# DSS_DSI0_DSI_TOP_VBUSP_CFG_DSI_0_DSI register map
Vendor: Texas Instruments
Peripheral module from a debugger description file (folder J7ES).
Registers are 32-bit, read-write, reset 0x0 unless marked. A register's access mark holds for its fields unless they carry their own. Offsets are as the file gives them; lines under a group give offsets from that group; [hi:lo] are bit positions; {n}, {i} and the like mark numbered series; 'fields as' and 'values as' point back to an identical list; <NAME> marks a mode.

## DSS_DSI0_DSI_TOP_VBUSP_CFG_DSI_0_DSI
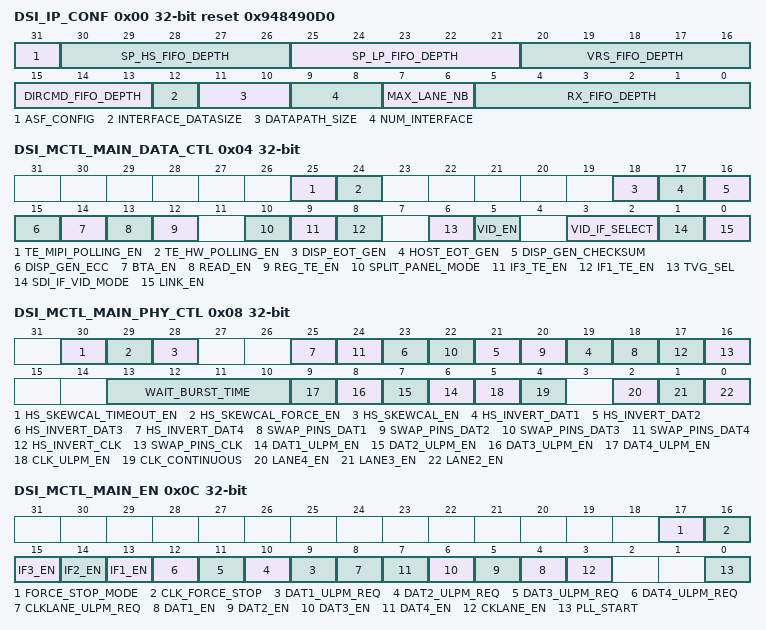
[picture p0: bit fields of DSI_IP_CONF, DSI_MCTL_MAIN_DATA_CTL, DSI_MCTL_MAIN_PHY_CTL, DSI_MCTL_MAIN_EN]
0x00 DSI_IP_CONF ro reset 0x948490D0 — IP Configuration for Controller
  [31] ASF_CONFIG — Active Safety Features [ASF] Configuration:
  [30:26] SP_HS_FIFO_DEPTH — SP_HS_FIFO_DEPTH : HS FIFO depth in sending path.
  [25:21] SP_LP_FIFO_DEPTH — SP_LP_FIFO_DEPTH : LP FIFO depth in sending path.
  [20:16] VRS_FIFO_DEPTH — VRS_FIFO_DEPTH : FIFO depth in the VRS block.
  [15:13] DIRCMD_FIFO_DEPTH — Direct Command FIFO Depth
  [12] INTERFACE_DATASIZE — SDI interface data width:
  [11:10] DATAPATH_SIZE — Internal Datapath.width
  [9:8] NUM_INTERFACE — Max Number of SDI interfaces
  [7:6] MAX_LANE_NB — Max Number of Lanes
  [5:0] RX_FIFO_DEPTH
0x04 DSI_MCTL_MAIN_DATA_CTL — Main Control - main control setting for datapath
  [25] TE_MIPI_POLLING_EN — TE_MIPI_POLLING_EN: enables TE Polling feature following MIPI recommendations [polling by software]
  [24] TE_HW_POLLING_EN — TE_HW_POLLING_EN: enables TE Polling feature following internal solution
  [18] DISP_EOT_GEN — DISP_EOT_GEN: display adds an EOT packet to its LPDT transfers
  [17] HOST_EOT_GEN — HOST_EOT_GEN: generates or not the EOT packet after a transfer in HS.
  [16] DISP_GEN_CHECKSUM — DISP_GEN_CHECKSUM: display generates checksum on its response packets.
  [15] DISP_GEN_ECC — DISP_GEN_ECC: display generates ECC on its response packets
  [14] BTA_EN — BTA_EN: enables BTA
  [13] READ_EN — READ_EN: enables read operation
  [12] REG_TE_EN — REG_TE_EN: enables Tearing Effect from register
  [10] SPLIT_PANEL_MODE — SPLIT_PANEL_MODE: when enabled, DSC stage controls data for split panel signle DPHY link
  [9] IF3_TE_EN — IF3_TE_EN: enables Tearing Effect on interface 3.
  [8] IF1_TE_EN — IF1_TE_EN: enables Tearing Effect on interface 1.
  [6] TVG_SEL — TVG_SEL: Test Video Generator is enabled [it is not the start signal!] - should not be set if if1_en = 1 and if1_mode = 1 [see
  [5] VID_EN — VID_EN: enables the video stream generator
  [3:2] VID_IF_SELECT — VID_IF_SELECT: Determines which video interface is active
  [1] SDI_IF_VID_MODE
  [0] LINK_EN — LINK_EN: enables [or not] the link]
0x08 DSI_MCTL_MAIN_PHY_CTL — Main control setting for the physical lanes and drive the static signals for D-PHY clock lane
  [30] HS_SKEWCAL_TIMEOUT_EN — HS_SKEWCAL_TIMEOUT_EN: Activate the HS SkewCal Control to occur after a timeout.
  [29] HS_SKEWCAL_FORCE_EN — HS_SKEWCAL_FORCE_EN: Force the HS SkewCal Control to occur immediately
  [28] HS_SKEWCAL_EN — HS_SKEWCAL_EN: activate the HS SkewCal Control at start of HS Transmission
  [2n+17] HS_INVERT_DAT{n} (n=1..4) — HS_INVERT_DAT
  [2n+16] SWAP_PINS_DAT{n} (n=1..4) — SWAP_PINS_DAT
  [17] HS_INVERT_CLK — HS_INVERT_CLK: invert HS signal on clock lane
  [16] SWAP_PINS_CLK — SWAP_PINS_CLK: swap pins on clock lane
  [13:10] WAIT_BURST_TIME — WAIT_BURST_TIME: delay to respect between two HS bursts.
  [n+5] DAT{n}_ULPM_EN (n=1..4) — DAT{n}_ULPM_EN: data lane {n} can be switched in ULP mode
  [5] CLK_ULPM_EN — CLK_ULPM_EN: specifies that clock lane can be switched in ULP mode [on demand]
  [4] CLK_CONTINUOUS — CLK_CONTINUOUS: clock lane should remain in HS sending mode [no return in STOP state]
  [2] LANE4_EN — LANE4_EN: enables the fourth lane [ controls DCB FSM]
  [1] LANE3_EN — LANE3_EN: enables the third lane [ controls DCB FSM]
  [0] LANE2_EN — LANE2_EN: enables the second lane [ controls DCB FSM]
0x0C DSI_MCTL_MAIN_EN — Control start/stop of the DSI link
  [17] FORCE_STOP_MODE — FORCE_STOP_MODE: when enabled, data lanes are forced back in STOP mode - this value should remain asserted for 10 us minimum
  [16] CLK_FORCE_STOP — CLK_FORCE_STOP : force clock lanes back in STOP mode - this value should remain asserted for 10 us minimum
  [15] IF3_EN — IF3_EN: enables DSC interface [i.e.
  [14] IF2_EN — IF2_EN: enables DPI interface [i.e.
  [13] IF1_EN — IF1_EN: enables SDI interface [i.e.
  [n+8] DAT{n}_ULPM_REQ (n=1..4) — DAT{n}_ULPM_REQ: switches data lane {n} in ULP mode
  [8] CLKLANE_ULPM_REQ — CLKLANE_ULPM_REQ: switches clock lane in ULP mode
  [n+3] DAT{n}_EN (n=1..4)
  [3] CKLANE_EN
  [0] PLL_START — PLL_START: enables the PLL [when set, the PLL is started]
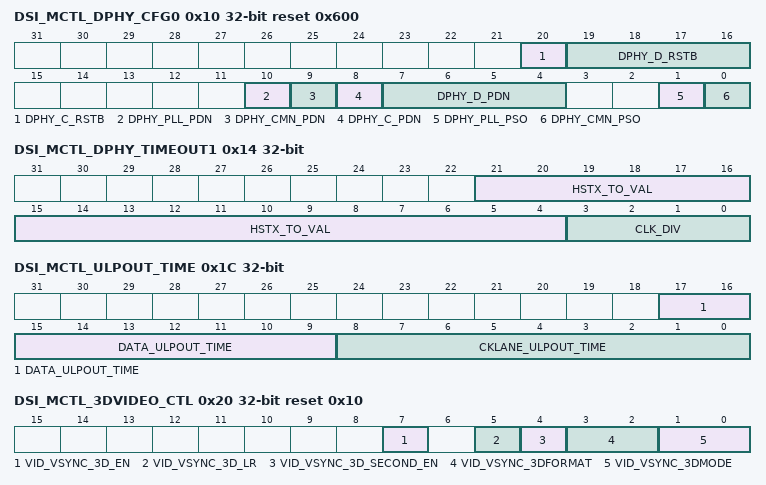
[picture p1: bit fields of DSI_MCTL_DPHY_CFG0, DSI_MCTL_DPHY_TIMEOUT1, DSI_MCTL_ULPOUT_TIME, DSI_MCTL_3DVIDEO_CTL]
0x10 DSI_MCTL_DPHY_CFG0 reset 0x600 — DPHY Power and Reset Control
  [20] DPHY_C_RSTB — Drives dphy_c_rstb output
  [19:16] DPHY_D_RSTB — Drives dphy_d_rstb output
  [10] DPHY_PLL_PDN — Drives dphy_pll_pdn output
  [9] DPHY_CMN_PDN — Drives dphy_cmn_pdn output
  [8] DPHY_C_PDN — Drives dphy_c_pdn output
  [7:4] DPHY_D_PDN — Drives dphy_d_pdn output
  [1] DPHY_PLL_PSO — Drives dphy_pll_pso output
  [0] DPHY_CMN_PSO — Drives dphy_cmn_pso output
0x14 DSI_MCTL_DPHY_TIMEOUT1 — Main DPHY time-out settings. To better understand the way this register is used, please refer to Section : DSI checks (DC) - the counters are based on tx_byte_hs_clk and NOT on sys_clk
  [21:4] HSTX_TO_VAL — HSTX_TO_VAL: HS TX time-out detection value
  [3:0] CLK_DIV — CLK_DIV: clock division ratio
0x18 DSI_MCTL_DPHY_TIMEOUT2 — To better understand the way this register is used, please refer to Section : DSI checks (DC) - the counters are on tx_byte_hs_clk and not on sys_clk
  [17:0] LPRX_TO_VAL — LPRX_TO_VAL: LP RX time-out detection value
0x1C DSI_MCTL_ULPOUT_TIME — Specify time to leave ULP mode. The time-out is reached when the ulpout counter reaches 1000x xxx_ulpout_time and is based upon the system clock
  [17:9] DATA_ULPOUT_TIME — DATA_ULPOUT_TIME: specify what the duration is to leave ULP mode is [for data lane[s] in system clock cycles
  [8:0] CKLANE_ULPOUT_TIME — CKLANE_ULPOUT_TIME: specify what the duration is to leave ULP mode is [for clock lane] in system clock cycles
0x20 DSI_MCTL_3DVIDEO_CTL reset 0x10 — 3D Video mode stream control
  [7] VID_VSYNC_3D_EN — VID_VSYNC_3D_EN: Enable 3D Control this selects the 3D operation for VSYNC and video data control
  [5] VID_VSYNC_3D_LR — VID_VSYNC_3D_LR: When 3D mode is enabled, this allows to choose which field to start the video stream
  [4] VID_VSYNC_3D_SECOND_EN — VID_VSYNC_3D_SECOND_EN: When 3D mode is enabled, this allows to choose if a second VSYNC is enabled between L and R images
  [3:2] VID_VSYNC_3DFORMAT — VID_VSYNC_3DFORMAT: video 3D Format for VSYNC Control Parameter1
  [1:0] VID_VSYNC_3DMODE — VID_VSYNC_3DMODE: video 3D mode for VSYNC Control Parameter1
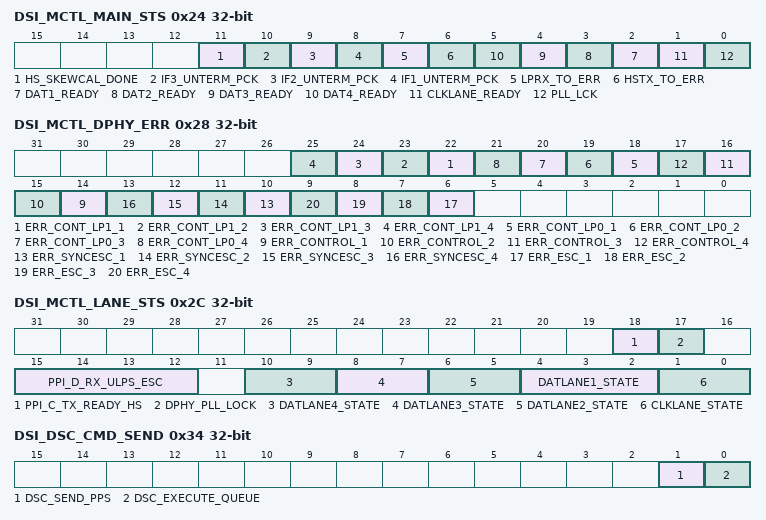
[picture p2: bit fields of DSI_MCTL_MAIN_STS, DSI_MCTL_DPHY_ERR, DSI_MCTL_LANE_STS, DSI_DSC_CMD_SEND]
0x24 DSI_MCTL_MAIN_STS ro — Status of the DSI link
  [11] HS_SKEWCAL_DONE — HS_SKEWCAL_DONE: HS SkewCal Control Done at start of HS Transmission
  [10] IF3_UNTERM_PCK — IF3_UNTERM_PCK: Indicates an unterminated packet on DSC interface
  [9] IF2_UNTERM_PCK — IF2_UNTERM_PCK: Indicates an unterminated packet on DPI interface
  [8] IF1_UNTERM_PCK — IF1_UNTERM_PCK: Indicates an unterminated packet on SDI Interface
  [7] LPRX_TO_ERR — LPRX_TO_ERR: Indicates an LP_RX time-out error
  [6] HSTX_TO_ERR — HSTX_TO_ERR: Indicates an HS_TX time-out error
  [n+1] DAT{n}_READY (n=1..4) — DAT{n}_READY: Indicates data lane {n} is ready
  [1] CLKLANE_READY — CLKLANE_READY: Indicates the clock lane is ready [normal DSI operation can start]
  [0] PLL_LCK — PLL_LCK: Indicates PLL is locked - data coming from DCB [if DSI link is PLL master] or copy of pll_en [if DSI link is slave]
0x28 DSI_MCTL_DPHY_ERR ro — Errors reported from DPHY lanes - See description in DPHY inputs and outputs
  [n+21] ERR_CONT_LP1_{n} (n=1..4), [n+17] ERR_CONT_LP0_{n} (n=1..4), [n+13] ERR_CONTROL_{n} (n=1..4), [n+9] ERR_SYNCESC_{n} (n=1..4), [n+5] ERR_ESC_{n} (n=1..4)
0x2C DSI_MCTL_LANE_STS ro — DPHY Lane and PLL status information
  [18] PPI_C_TX_READY_HS — Value of ppi_c_tx_ready_hs input
  [17] DPHY_PLL_LOCK — Value of dphy_pll_lock input
  [15:12] PPI_D_RX_ULPS_ESC — Value of ppi_d_rx_ulps_esc input
  [10:9] DATLANE4_STATE — DATLANE4_STATE: state of the data lane 4
  [8:7] DATLANE3_STATE — DATLANE3_STATE: state of the data lane 3
  [6:5] DATLANE2_STATE — DATLANE2_STATE: state of the data lane 2
  [4:2] DATLANE1_STATE — DATLANE1_STATE: state of the data lane 1
  [1:0] CLKLANE_STATE — CLKLANE_STATE: state of the clock lane
0x30 DSI_DSC_MODE_CTL — DSC Mode Control register
  [0] DSC_MODE_EN — Enable DSC Mode Controls
0x34 DSI_DSC_CMD_SEND wo — DSC Command Control register. Write one to perform PPS set transfer or Execute Queue commands
  [1] DSC_SEND_PPS — Send PPS Command and Payload to the display
  [0] DSC_EXECUTE_QUEUE — Send Execute Queue Command to Synchonise the display drivers
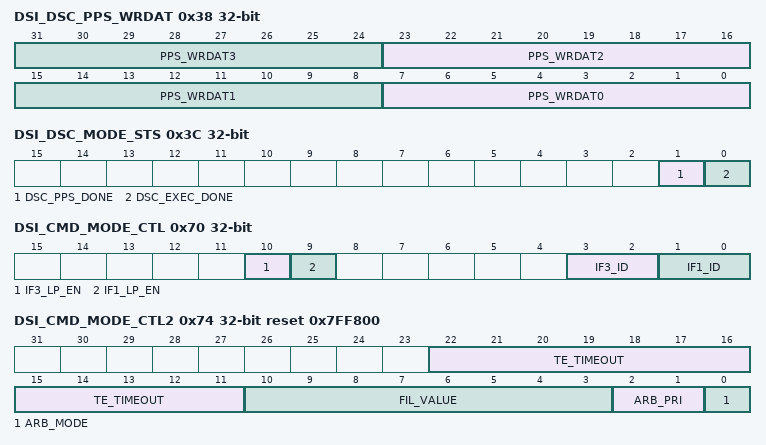
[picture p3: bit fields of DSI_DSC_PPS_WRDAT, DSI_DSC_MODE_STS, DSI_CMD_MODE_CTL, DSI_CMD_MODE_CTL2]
0x38 DSI_DSC_PPS_WRDAT — DSC PPS Write data to outgoing FIFO Buffer, byte 0 to 3; applicable to either Write or Read commands. Note that any writes to this register that exceed the programmed command payload size or the configured FIFO depth (whichever is smaller) will be ignored. Conversely, if the writes to this register are less than the programmed command payload size when the instruction to send the payload is given, the command payload will contain data from the previous contents of the FIFO for all unwritten bytes, and will therefore be corrupt.
  [8n+7:8n] PPS_WRDAT{n} (n=0..3) — WRDAT
0x3C DSI_DSC_MODE_STS ro — DSC Event Status Register
  [1] DSC_PPS_DONE — DSC PPS Command Sent
  [0] DSC_EXEC_DONE — DSC Execute Command Sent
0x40 DSI_MCTL_DPHY_SKEWCAL_TIMEOUT — Used in conjunction with HS_SKEWCAL_TIMEOUT_EN from to control periodic skew calibration
  [31:0] SKEWCAL_TO_VAL — SKEWCAL_TO_VAL: Timeout value
0x70 DSI_CMD_MODE_CTL — Command mode control
  [10] IF3_LP_EN — IF3_LP_EN: enable to send command from DSC interface in LP if possible
  [9] IF1_LP_EN — IF1_LP_EN: enable to send command from SDI interface in LP if possible
  [3:2] IF3_ID — IF3_ID: Virtual Channel ID of request from DSC interface command
  [1:0] IF1_ID — IF1_ID: Virtual Channel ID of request from SDI interface command
0x74 DSI_CMD_MODE_CTL2 reset 0x7FF800 — Command mode control
  [22:11] TE_TIMEOUT — TE_TIMEOUT : on TE request - length of TE response window before timeout.
  [10:3] FIL_VALUE — FIL_VALUE: value to use to fill packet during data underrun or to complete unterminated packet [referred as padding value]
  [2:1] ARB_PRI — ARB_PRI: in fixed mode, specify interface with higher priority SDI 01, DSC 10
  [0] ARB_MODE — ARB_MODE: arbitration mode
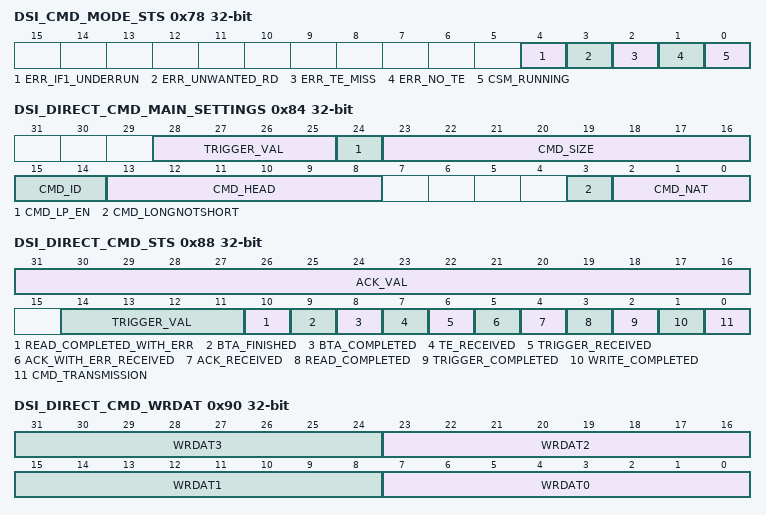
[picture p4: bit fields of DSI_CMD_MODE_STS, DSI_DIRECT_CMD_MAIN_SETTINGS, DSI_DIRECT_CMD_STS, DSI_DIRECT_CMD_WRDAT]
0x78 DSI_CMD_MODE_STS ro — Command Mode status
  [4] ERR_IF1_UNDERRUN — ERR_IF1_UNDERRUN: Indicates a data shortage occurs on IF1
  [3] ERR_UNWANTED_RD — ERR_UNWANTED_RD: Indicates a read request was received while read capability was not enabled
  [2] ERR_TE_MISS — ERR_TE_MISS: error: TE window time-out
  [1] ERR_NO_TE — ERR_NO_TE: error: no TE generated by display
  [0] CSM_RUNNING — CSM_RUNNING: Indicates CSM is running - command[s] are being proceeded
0x80 DSI_DIRECT_CMD_SEND wo — is not a real register. When this address is written (whatever its value is), it signals to the link that a direct command has to be sent. It is then a write only register.No specific mechanism is implemented to prevent the application sending two direct commands back-to-back. It is then applications responsibility to verify the completion of a first direct command before starting another direct command.Interlacing of command or video with direct command is managed by the DSI link using the different arbiters (see Command and register arbiter (CRA) and Video/command arbiter (VCA))
  [31:0] DIRECT_CMD_SEND — Initiate the direct command send operation
0x84 DSI_DIRECT_CMD_MAIN_SETTINGS — Main control of the Direct Command function.
  [28:25] TRIGGER_VAL — TRIGGER_VAL: trigger value if trigger request [see Note about trigger mapping]
  [24] CMD_LP_EN — CMD_LP_EN: enables LP sending for the command request
  [23:16] CMD_SIZE — CMD_SIZE: size, in bytes, of the command payload.
  [15:14] CMD_ID — CMD_ID: For a read/write command, Virtual Channel of the command
  [13:8] CMD_HEAD — CMD_HEAD: For a read/write command, datatype of the command
  [3] CMD_LONGNOTSHORT — CMD_LONGNOTSHORT: Tie this to '1' if a long packet has to be generated.
  [2:0] CMD_NAT — CMD_NAT: Type of the direct command:
0x88 DSI_DIRECT_CMD_STS ro — Direct Command Status: To ensure that the observed status bits are coherent and applicable to the last command message sent, it is recommended to clear this register between accesses by writing to direct_cmd_clr, otherwise the status of the different commands is logically ORed, making it difficult to differentiate between the status of each message.
  [31:16] ACK_VAL — ACK_VAL: if an acknowledge with error has been received, this field reports its value
  [14:11] TRIGGER_VAL — TRIGGER_VAL: if a trigger has been received, this field reports its value - refer to Note regarding trigger mapping
  [10] READ_COMPLETED_WITH_ERR — READ_COMPLETED_WITH_ERR: read command terminated with error
  [9] BTA_FINISHED — BTA_FINISHED: DSI link recovered link master role after a BTA request
  [8] BTA_COMPLETED — BTA_COMPLETED: indicates that BTA request completed
  [7] TE_RECEIVED — TE_RECEIVED: TE received
  [6] TRIGGER_RECEIVED — TRIGGER_RECEIVED: If command with BTA, this bit is set if an trigger was received
  [5] ACK_WITH_ERR_RECEIVED — ACKNOWLEDGE_WITH_ERR_RECEIVED: If command with BTA, this bit is set if an acknowledge with error was received
  [4] ACK_RECEIVED — ACKNOWLEDGE_RECEIVED: If command with BTA, this bit is set if an acknowledge with no error was received
  [3] READ_COMPLETED — READ_COMPLETED: read command request completed
  [2] TRIGGER_COMPLETED — TRIGGER_COMPLETED: trigger command request completed
  [1] WRITE_COMPLETED — WRITE_COMPLETED: write command request completed
  [0] CMD_TRANSMISSION — CMD_TRANSMISSION: a command is being sent
0x8C DSI_DIRECT_CMD_RD_INIT wo — This register is not a real register - when written it stops the read command process by emptying the FIFO and by stopping the reception of the data (RP does not consider the data that it receives and the system waits for the D-PHY to return to Tx STOP state).
  [31:0] STOP_READ_OPERATION
0x90 DSI_DIRECT_CMD_WRDAT — Write data to outgoing Direct Command FIFO, byte 0 to 3; applicable to either Write or Read commands. Note that any writes to this register that exceed the programmed command payload size or the configured FIFO depth (whichever is smaller) will be ignored. Conversely, if the writes to this register are less than the programmed command payload size when the instruction to send the payload is given, the command payload will contain data from the previous contents of the FIFO for all unwritten bytes, and will therefore be corrupt. Note also that values written to the FIFO which are intended for transmission of single parameter write transaction must set the MS bytes to zero to comply with DSI standard requirements.
  [8n+7:8n] WRDAT{n} (n=0..3) — WRDAT
0x94 DSI_DIRECT_CMD_FIFO_RST wo — Reset the write FIFO. This register is not a real register - when written it reset the FIFO pointer
  [31:0] CMD_FIFO_RST — Direct Command FIFO Reset
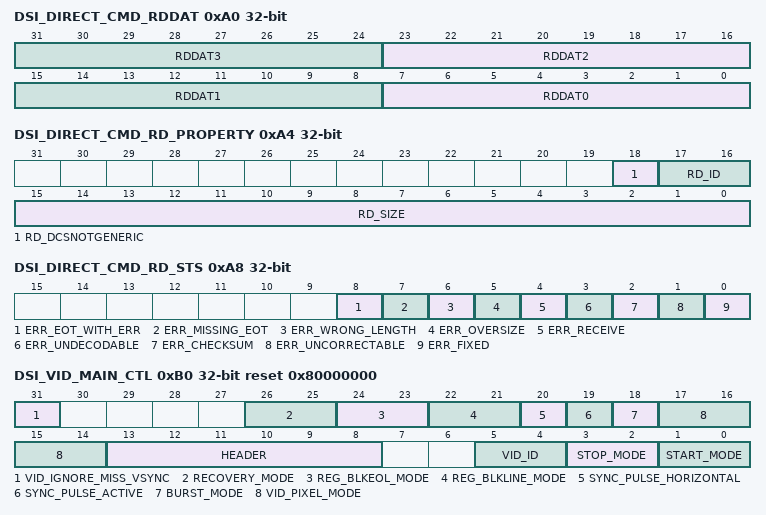
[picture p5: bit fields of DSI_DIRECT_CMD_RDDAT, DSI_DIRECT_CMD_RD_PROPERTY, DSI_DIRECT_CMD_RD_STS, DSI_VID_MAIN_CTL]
0xA0 DSI_DIRECT_CMD_RDDAT ro — Data from incoming Direct Command receive path, byte 0 to 3. NOTE: SW must mask any bytes which are in excess of the actual message size (e.g. for a 2-byte message payload, take data from bytes [1:0] and mask off bytes [3:2])
  [8n+7:8n] RDDAT{n} (n=0..3) — RDDAT
0xA4 DSI_DIRECT_CMD_RD_PROPERTY ro — read command characteristics
  [18] RD_DCSNOTGENERIC — RD_DCSNOTGENERIC: Type of read command [DCS or generic]
  [17:16] RD_ID — RD_ID: Virtual channel of the read received
  [15:0] RD_SIZE — RD_SIZE: Size of the read data received
0xA8 DSI_DIRECT_CMD_RD_STS ro — Status of the read command received. It is recommended to clear between two direct commands (at least between 2 read) in order to see coherent status
  [8] ERR_EOT_WITH_ERR — ERR_EOT_WITH_ERR: EOT received with error
  [7] ERR_MISSING_EOT — ERR_MISSING_EOT: EOT requested but not received
  [6] ERR_WRONG_LENGTH — ERR_WRONG_LENGTH : length error has been detected.
  [5] ERR_OVERSIZE — ERR_OVERSIZE : packet size exceeds maximum
  [4] ERR_RECEIVE — ERR_RECEIVE : received packet not complete.
  [3] ERR_UNDECODABLE — ERR_UNDECODABLE : command opcode not understood
  [2] ERR_CHECKSUM — ERR_CHECKSUM: error[s] detected by checksum
  [1] ERR_UNCORRECTABLE — ERR_UNCORRECTABLE : more than 1 error detected by ECC
  [0] ERR_FIXED — ERR_FIXED : one error detected and fixed by ECC
0xB0 DSI_VID_MAIN_CTL reset 0x80000000 — Video mode main control
  [31] VID_IGNORE_MISS_VSYNC — VID_IGNORE_MISSING_SYNC: When mode is enabled, this allows the video stream to go to IDLE during VFP and wait for new VSYNC without link failing to recovery
  [26:25] RECOVERY_MODE — RECOVERY_MODE: specify recovery mode
  [24:23] REG_BLKEOL_MODE — REG_BLKEOL_MODE: behavior during end of line in burst mode - same coding as reg_blkline_mode
  [22:21] REG_BLKLINE_MODE — REG_BLKLINE_MODE : behavior during blanking time [1x: LP,
  [20] SYNC_PULSE_HORIZONTAL — SYNC_PULSE_HORIZONTAL: syncs are pulse [1] or event [0] all the time [DSI protocol v1.00..._r6 and later] - to be set only when sync_pulse_active = 1
  [19] SYNC_PULSE_ACTIVE — SYNC_PULSE_ACTIVE: syncs are pulse [1] or event [0] during active area [DSI protocol v1.00..._r3 and before]
  [18] BURST_MODE — BURST_MODE: signals if system works in burst mode or not
  [17:14] VID_PIXEL_MODE
  [13:8] HEADER — HEADER : specify the datatype of RGB packets
  [5:4] VID_ID — VID_ID : specify the Virtual Channel Identifier of the video packets
  [3:2] STOP_MODE — STOP_MODE : video stop point [see description in Video Stream Generator [VSG] section] .[The configurations where the frame stops at the end of any line
  [1:0] START_MODE — START_MODE: video entry point [see description in Video Stream Generator [VSG] section][The configuration where the frame starts with a VFP -
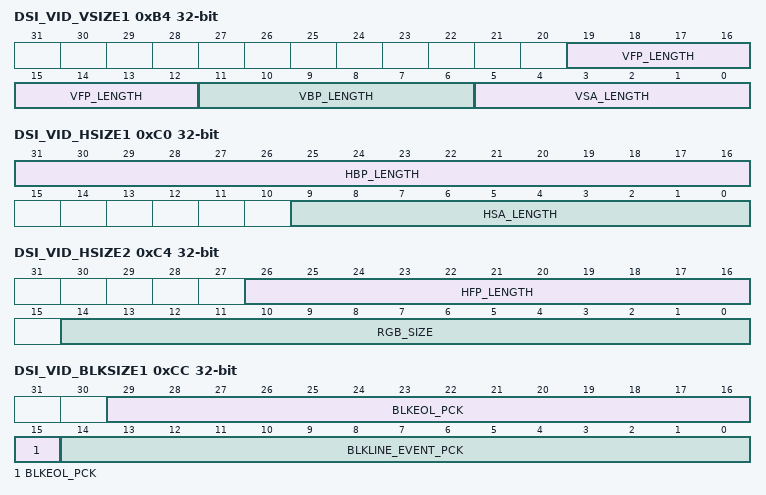
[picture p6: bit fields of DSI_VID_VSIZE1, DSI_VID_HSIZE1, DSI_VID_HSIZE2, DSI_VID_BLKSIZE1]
0xB4 DSI_VID_VSIZE1 — Image vertical Sync and Blanking settings
  [19:12] VFP_LENGTH — VFP_LENGTH: length of the VFP [in lines]
  [11:6] VBP_LENGTH — VBP_LENGTH: length of the VBP [in lines]
  [5:0] VSA_LENGTH — VSA_LENGTH: duration of the VSYNC pulse [in lines]
0xB8 DSI_VID_VSIZE2 — Image vertical active line setting
  [12:0] VACT_LENGTH — VACT_LENGTH: vertical length of active area [in line]
0xC0 DSI_VID_HSIZE1 — Image horizontal sync and Blanking setting Active line Pulse Mode: |____hsync_____|____hbp_____|________________hact_______________|_______hfp________| |_HSS_HSA_HSE__|HDR_HBP_CRC_|HDR_____________HACT____________CRC|HDR____HFP_____CRC|_HSS_ Active line Event Mode: |____hsync_____|____hbp_____|________________hact_______________|_______hfp________| |_HSS_|HDR___HSA+HBP____CRC_|HDR_____________HACT____________CRC|HDR____HFP_____CRC|_HSS_
  [31:16] HBP_LENGTH — HBP_LENGTH: length of HBP [in bytes] - if 0, HBP packet is sent with 0 payload
  [9:0] HSA_LENGTH — HSA_LENGTH: duration of HSYNC pulse [in bytes]
0xC4 DSI_VID_HSIZE2 — Image horizontal byte size setting
  [26:16] HFP_LENGTH — HFP_LENGTH: length of HFP [in bytes] - if 0, no HFP packet is sent
  [14:0] RGB_SIZE — RGB_SIZE: size [in byte] of the RGB packet
0xCC DSI_VID_BLKSIZE1 — blanking packet size
  [29:15] BLKEOL_PCK — BLKEOL_PCK: packet length [in byte] on end of line if burst mode [reg_blkeol_mode = 0b0x]
  [14:0] BLKLINE_EVENT_PCK — BLKLINE_EVENT_PCK: packet length [in byte] in blanking line if line has to be filled with a packet [reg_blkline_mode = 0b0x] and sync is an event
0xD0 DSI_VID_BLKSIZE2 — Pulse Mode blanking packet size
  [14:0] BLKLINE_PULSE_PCK — BLKLINE_PULSE_PCK: packet length in blanking line if line has to be filled with a packet [reg_blkline_mode = 0b0x] and sync is a pulse
0xD8 DSI_VID_PCK_TIME — Packet duration
  [14:0] BLKEOL_DURATION — BLKEOL_DURATION: specify the duration in clock cycles of the BLLP period [used for burst mode]
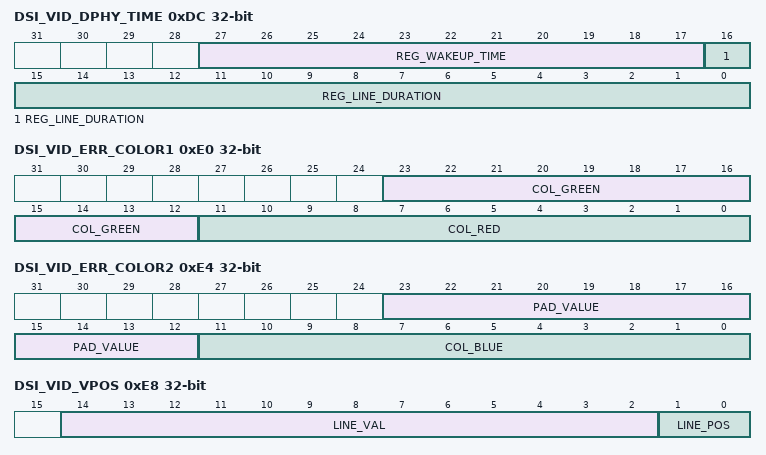
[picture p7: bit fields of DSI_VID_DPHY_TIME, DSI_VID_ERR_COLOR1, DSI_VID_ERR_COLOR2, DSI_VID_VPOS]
0xDC DSI_VID_DPHY_TIME — Time of D-PHY behavior for wakeup time and Line duration for LP during horozontal blanking lines
  [27:17] REG_WAKEUP_TIME — REG_WAKEUP_TIME: estimated time [in clock cycles] to perform LP-&gt;HS on D-PHY
  [16:0] REG_LINE_DURATION — REG_LINE_DURATION: duration -in clock cycles - of the blanking area for VSA/VBP and VFP lines - considered when reg_blkline_mode = 1b1x
0xE0 DSI_VID_ERR_COLOR1 — error color (green and red)
  [23:12] COL_GREEN — COL_GREEN: green component of the fill color
  [11:0] COL_RED — COL_RED: red component of the fill color
0xE4 DSI_VID_ERR_COLOR2 — error color (blue and padding)
  [23:12] PAD_VALUE — PAD_VALUE: byte used to pad data [when system does not know exactly where it is]
  [11:0] COL_BLUE — COL_BLUE: blue component of the fill color
0xE8 DSI_VID_VPOS ro — vertical position
  [14:2] LINE_VAL — LINE_VAL: line number of the current area
  [1:0] LINE_POS — LINE_POS: position in the frame [see description in Video Stream Generator]
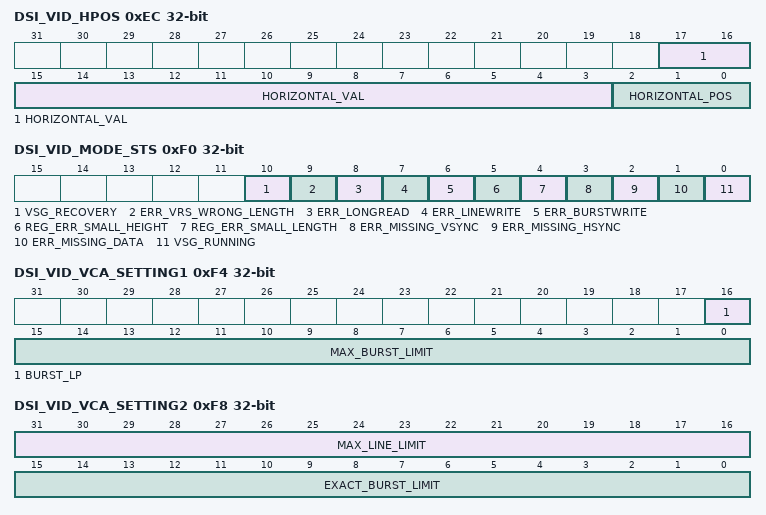
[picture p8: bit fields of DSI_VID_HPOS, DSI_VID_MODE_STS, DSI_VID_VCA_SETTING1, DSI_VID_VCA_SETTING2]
0xEC DSI_VID_HPOS ro — Horizontal Position
  [17:3] HORIZONTAL_VAL — HORIZONTAL_VAL: position in the current horizontal area [in clock cycles]
  [2:0] HORIZONTAL_POS — HORIZONTAL_POS: position in the line [see description in Video Stream Generator]
0xF0 DSI_VID_MODE_STS ro — Video mode status and error reporting
  [10] VSG_RECOVERY — VSG_RECOVERY: specifies whether the VSG is in recovery mode or not
  [9] ERR_VRS_WRONG_LENGTH — ERR_VRS_WRONG_LENGTH: signals that packets in SDI interface differ from the expected size [as specified by rgb_size]
  [8] ERR_LONGREAD — ERR_LONGREAD: signals the read was too long
  [7] ERR_LINEWRITE — ERR_LINEWRITE: signals the long packet is too long to pass during a long slot
  [6] ERR_BURSTWRITE — ERR_BURSTWRITE: signals a long packet has been sent during active area
  [5] REG_ERR_SMALL_HEIGHT — REG_ERR_SMALL_HEIGHT: fewer lines than expected between 2 VSYNC
  [4] REG_ERR_SMALL_LENGTH — REG_ERR_SMALL_LENGTH: fewer bytes received than expected between 2 HSYNC.
  [3] ERR_MISSING_VSYNC — ERR_MISSING_VSYNC: missing VSYNC
  [2] ERR_MISSING_HSYNC — ERR_MISSING_HSYNC: missing HSYNC
  [1] ERR_MISSING_DATA — ERR_MISSING_DATA: data starvation at input of the VSG.
  [0] VSG_RUNNING — VSG_RUNNING: VSG is running [1] or stopped [0]
0xF4 DSI_VID_VCA_SETTING1 — VCA control register 1
  [16] BURST_LP — BURST_LP: after an active line, the system can switch in LP [1] or should complete the line with NULL packet [0]
  [15:0] MAX_BURST_LIMIT — MAX_BURST_LIMIT: size of the 'biggest' burst packet [packet that fits after RGB in burst mode]
0xF8 DSI_VID_VCA_SETTING2 — VCA control register 2
  [31:16] MAX_LINE_LIMIT — MAX_LINE_LIMIT: maximum size of the line packet [packet that fits in blanking line]
  [15:0] EXACT_BURST_LIMIT — EXACT_BURST_LIMIT: exact maximum size of the burst packet [packet that fits after RGB in burst mode]
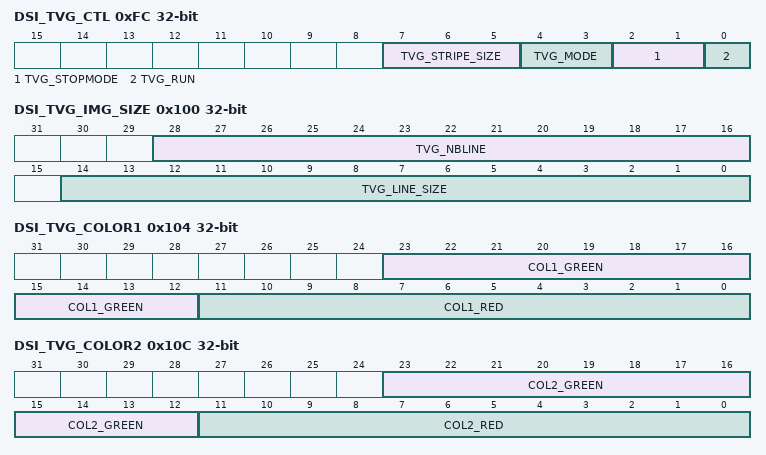
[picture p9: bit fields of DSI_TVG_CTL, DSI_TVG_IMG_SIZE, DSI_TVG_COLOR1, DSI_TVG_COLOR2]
0xFC DSI_TVG_CTL — Main control of the TVG
  [7:5] TVG_STRIPE_SIZE — TVG_STRIPE_SIZE: size of the stripe [in pixels] - defined by 2
  [4:3] TVG_MODE — TVG_MODE: TVG display mode :
  [2:1] TVG_STOPMODE — TVG_STOPMODE: stop mode:
  [0] TVG_RUN — TVG_RUN: start/stop of the TVG
0x100 DSI_TVG_IMG_SIZE — TVG Generated image size
  [28:16] TVG_NBLINE — TVG_NBLINE: Number of lines per frame
  [14:0] TVG_LINE_SIZE — TVG_LINE_SIZE: Number of bytes per line
0x104 DSI_TVG_COLOR1 — Color 1 of the dummy frame G, R
  [23:12] COL1_GREEN — COL1_GREEN: green component of the color 1
  [11:0] COL1_RED — COL1_RED: red component of the color 1
0x108 DSI_TVG_COLOR1_BIS — Color 1 of the dummy frame , B
  [11:0] COL1_BLUE — COL1_BLUE: blue component of the color 1
0x10C DSI_TVG_COLOR2 — Color 2 of the dummy frame, G, R
  [23:12] COL2_GREEN — COL2_GREEN: green component of the color 2
  [11:0] COL2_RED — COL2_RED: red component of the color 2
0x110 DSI_TVG_COLOR2_BIS — Color 2 of the dummy frame, B
  [11:0] COL2_BLUE — COL2_BLUE: blue component of the color 2
0x114 DSI_TVG_STS ro — TVG status register
  [0] TVG_RUNNING — TVG_RUNNING: status of the TVG
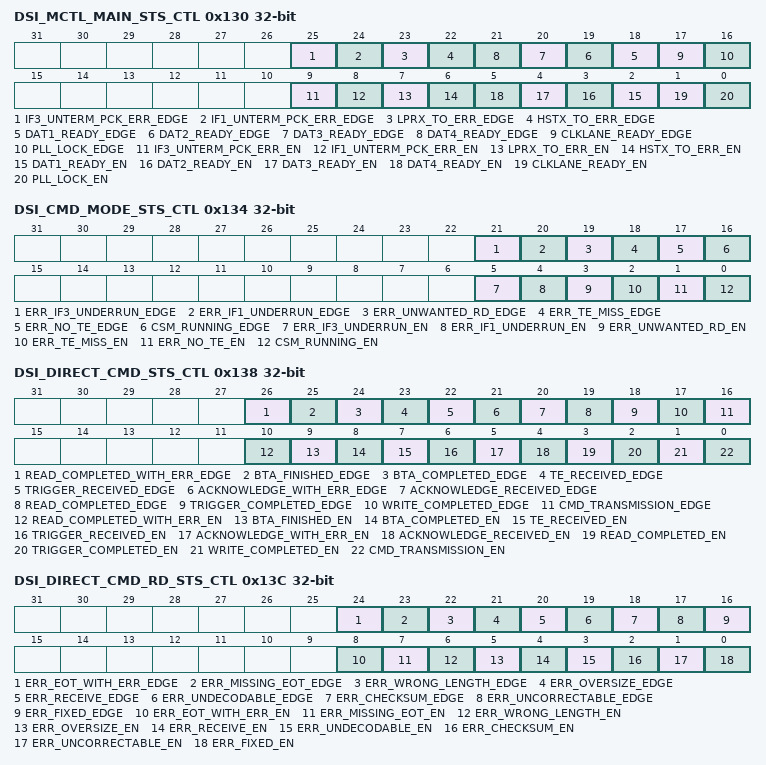
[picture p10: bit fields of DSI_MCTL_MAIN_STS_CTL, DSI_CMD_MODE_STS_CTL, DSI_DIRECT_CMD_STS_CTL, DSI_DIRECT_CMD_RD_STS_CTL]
0x130 DSI_MCTL_MAIN_STS_CTL — Controls the enabling and edge detection of main ctrl status bits EDGE = 0 captures the rising edge of the event, EDGE= 1 captures falling edge.
  [25] IF3_UNTERM_PCK_ERR_EDGE — IF3_UNTERM_PCK_ERR_EDGE: edge detection of if3_unterm_pck_err
  [24] IF1_UNTERM_PCK_ERR_EDGE — IF1_UNTERM_PCK_ERR_EDGE: edge detection of if1_unterm_pck_err
  [23] LPRX_TO_ERR_EDGE — LPRX_TO_ERR_EDGE: edge detection of LP_RX time-out error
  [22] HSTX_TO_ERR_EDGE — HSTX_TO_ERR_EDGE: edge detection of HS_TX time-out error
  [n+17] DAT{n}_READY_EDGE (n=1..4) — DAT{n}_READY_EDGE: edge detection of dat{n}_ready
  [17] CLKLANE_READY_EDGE — CLKLANE_READY_EDGE: edge detection of clklane_ready
  [16] PLL_LOCK_EDGE — PLL_LOCK_EDGE: edge detection of PLL lock
  [9] IF3_UNTERM_PCK_ERR_EN — IF3_UNTERM_PCK_ERR_EN: enables if3_unterm_pck_err
  [8] IF1_UNTERM_PCK_ERR_EN — IF1_UNTERM_PCK_ERR_EN: enables if1_unterm_pck_err
  [7] LPRX_TO_ERR_EN — LPRX_TO_ERR_EN: enables lprx_to_err
  [6] HSTX_TO_ERR_EN — HSTX_TO_ERR_EN: enables hstx_to_err
  [n+1] DAT{n}_READY_EN (n=1..4) — DAT{n}_READY_EN: enables dat{n}_ready
  [1] CLKLANE_READY_EN — CLKLANE_READY_EN: enables clklane_ready
  [0] PLL_LOCK_EN — PLL_LOCK_EN: enables PLL lock
0x134 DSI_CMD_MODE_STS_CTL — Controls the enabling and edge detection of command status bits EDGE = 0 captures the rising edge of the event, EDGE= 1 captures falling edge.
  [21] ERR_IF3_UNDERRUN_EDGE — ERR_IF3_UNDERRUN_EDGE: edge detection of err_IF3_underrun
  [20] ERR_IF1_UNDERRUN_EDGE — ERR_IF1_UNDERRUN_EDGE: edge detection of err_IF1_underrun
  [19] ERR_UNWANTED_RD_EDGE — ERR_UNWANTED_RD_EDGE: edge detection of err_unwanted_rd
  [18] ERR_TE_MISS_EDGE — ERR_TE_MISS_EDGE: edge detection of err_te_miss
  [17] ERR_NO_TE_EDGE — ERR_NO_TE_EDGE: edge detection of err_no_te
  [16] CSM_RUNNING_EDGE — CSM_RUNNING_EDGE: edge detection of CSM running
  [5] ERR_IF3_UNDERRUN_EN — ERR_IF3_UNDERRUN_EN: enables err_IF3_underrun
  [4] ERR_IF1_UNDERRUN_EN — ERR_IF1_UNDERRUN_EN: enables err_IF1_underrun
  [3] ERR_UNWANTED_RD_EN — ERR_UNWANTED_RD_EN: enables err_unwanted_rd
  [2] ERR_TE_MISS_EN — ERR_TE_MISS_EN: enables err_te_miss
  [1] ERR_NO_TE_EN — ERR_NO_TE_EN: enables err_no_te
  [0] CSM_RUNNING_EN — CSM_RUNNING_EN: enables signaling of CSM running
0x138 DSI_DIRECT_CMD_STS_CTL — Controls the enabling and edge detection of Direct Command status bits
  [26] READ_COMPLETED_WITH_ERR_EDGE — READ_COMPLETED_WITH_ERR_EDGE: edge detection of read detection completed with errors
  [25] BTA_FINISHED_EDGE — BTA_FINISHED_EDGE: edge detection of BTA completion detection
  [24] BTA_COMPLETED_EDGE — BTA_COMPLETED_EDGE: edge detection of BTA request completed
  [23] TE_RECEIVED_EDGE — TE_RECEIVED_EDGE: edge detection of TE received
  [22] TRIGGER_RECEIVED_EDGE — TRIGGER_RECEIVED_EDGE: edge detection of trigger
  [21] ACKNOWLEDGE_WITH_ERR_EDGE — ACKNOWLEDGE_WITH_ERR_EDGE: edge detection of acknowledge with error
  [20] ACKNOWLEDGE_RECEIVED_EDGE — ACKNOWLEDGE_RECEIVED_EDGE: edge detection of acknowledge
  [19] READ_COMPLETED_EDGE — READ_COMPLETED_EDGE: edge detection of read request completed
  [18] TRIGGER_COMPLETED_EDGE — TRIGGER_COMPLETED_EDGE: edge detection of trigger request completed
  [17] WRITE_COMPLETED_EDGE — WRITE_COMPLETED_EDGE: edge detection of detection of write request completed
  [16] CMD_TRANSMISSION_EDGE — CMD_TRANSMISSION_EDGE: edge detection of cmd_transmission
  [10] READ_COMPLETED_WITH_ERR_EN — READ_COMPLETED_WITH_ERR_EN: enables detection of read completed with errors
  [9] BTA_FINISHED_EN — BTA_FINISHED_EN: enables BTA completion detection
  [8] BTA_COMPLETED_EN — BTA_COMPLETED_EN: enables BTA request completed
  [7] TE_RECEIVED_EN — TE_RECEIVED_EN: enables TE received
  [6] TRIGGER_RECEIVED_EN — TRIGGER_RECEIVED_EN: enables trigger
  [5] ACKNOWLEDGE_WITH_ERR_EN — ACKNOWLEDGE_WITH_ERR_EN: enables acknowledge with error
  [4] ACKNOWLEDGE_RECEIVED_EN — ACKNOWLEDGE_RECEIVED_EN: enables acknowledge
  [3] READ_COMPLETED_EN — READ_COMPLETED_EN: enables read request completed
  [2] TRIGGER_COMPLETED_EN — TRIGGER_COMPLETED_EN: enables trigger_completed
  [1] WRITE_COMPLETED_EN — WRITE_COMPLETED_EN: enables write_completed
  [0] CMD_TRANSMISSION_EN — CMD_TRANSMISSION_EN: enables detection of cmd_transmission
0x13C DSI_DIRECT_CMD_RD_STS_CTL — Controls the enabling and edge detection of read commands error
  [24] ERR_EOT_WITH_ERR_EDGE — ERR_EOT_WITH_ERR_EDGE: edge detection of err_eot_with_err
  [23] ERR_MISSING_EOT_EDGE — ERR_MISSING_EOT_EDGE: edge detection of err_missing_eot
  [22] ERR_WRONG_LENGTH_EDGE — ERR_WRONG_LENGTH_EDGE: edge detection of err_wrong_length
  [21] ERR_OVERSIZE_EDGE — ERR_OVERSIZE_EDGE: edge detection of err_oversize
  [20] ERR_RECEIVE_EDGE — ERR_RECEIVE_EDGE: edge detection of err_receive
  [19] ERR_UNDECODABLE_EDGE — ERR_UNDECODABLE_EDGE: edge detection of err_undecodable
  [18] ERR_CHECKSUM_EDGE — ERR_CHECKSUM_EDGE: edge detection of err_checksum
  [17] ERR_UNCORRECTABLE_EDGE — ERR_UNCORRECTABLE_EDGE: edge detection of err_uncorrectable
  [16] ERR_FIXED_EDGE — ERR_FIXED_EDGE: edge detection of err_fixed
  [8] ERR_EOT_WITH_ERR_EN — ERR_EOT_WITH_ERR_EN: enables err_eot_with_err
  [7] ERR_MISSING_EOT_EN — ERR_MISSING_EOT_EN: enables err_missing_eot
  [6] ERR_WRONG_LENGTH_EN — ERR_WRONG_LENGTH_EN: enables err_wrong_length
  [5] ERR_OVERSIZE_EN — ERR_OVERSIZE_EN: enables err_oversize
  [4] ERR_RECEIVE_EN — ERR_RECEIVE_EN: enables err_receive
  [3] ERR_UNDECODABLE_EN — ERR_UNDECODABLE_EN: enables err_undecodable
  [2] ERR_CHECKSUM_EN — ERR_CHECKSUM_EN: enables err_checksum
  [1] ERR_UNCORRECTABLE_EN — ERR_UNCORRECTABLE_EN: enables err_uncorrectable
  [0] ERR_FIXED_EN — ERR_FIXED_EN: enables err_fixed
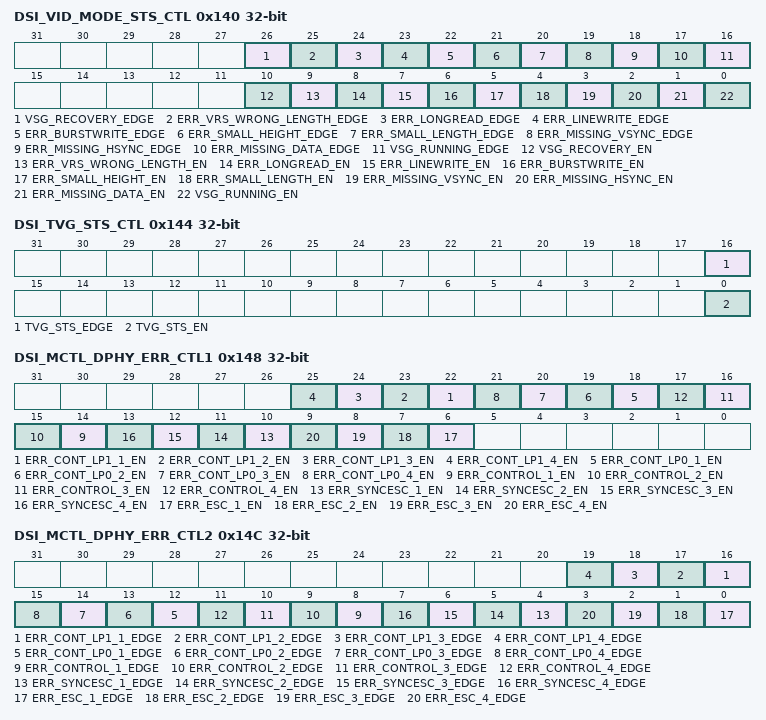
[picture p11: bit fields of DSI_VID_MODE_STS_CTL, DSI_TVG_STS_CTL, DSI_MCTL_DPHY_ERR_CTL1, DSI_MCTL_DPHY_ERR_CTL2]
0x140 DSI_VID_MODE_STS_CTL — Control the enabling and edge detection of VSG status bits
  [26] VSG_RECOVERY_EDGE — VSG_RECOVERY_EDGE: edge detection of vsg_recovery
  [25] ERR_VRS_WRONG_LENGTH_EDGE — ERR_VRS_WRONG_LENGTH_EDGE: edge detection of err_vrs_wrong_length
  [24] ERR_LONGREAD_EDGE — ERR_LONGREAD_EDGE: edge detection of err_longread
  [23] ERR_LINEWRITE_EDGE — ERR_LINEWRITE_EDGE: edge detection of err_line_write
  [22] ERR_BURSTWRITE_EDGE — ERR_BURSTWRITE_EDGE: edge detection of err_burst_write
  [21] ERR_SMALL_HEIGHT_EDGE — ERR_SMALL_HEIGHT_EDGE: edge detection of unaligned line number
  [20] ERR_SMALL_LENGTH_EDGE — ERR_SMALL_LENGTH_EDGE: edge detection of unaligned size
  [19] ERR_MISSING_VSYNC_EDGE — ERR_MISSING_VSYNC_EDGE: edge detection of detection of missing VSYNC
  [18] ERR_MISSING_HSYNC_EDGE — ERR_MISSING_HSYNC_EDGE: edge detection of detection of missing HSYNC
  [17] ERR_MISSING_DATA_EDGE — ERR_MISSING_DATA_EDGE: edge detection of data miss detection
  [16] VSG_RUNNING_EDGE — VSG_RUNNING_EDGE: edge detection of VSG status observation
  [10] VSG_RECOVERY_EN — VSG_RECOVERY_EN: enables vsg_recovery
  [9] ERR_VRS_WRONG_LENGTH_EN — ERR_VRS_WRONG_LENGTH_EN: enables err_vrs_wrong_length
  [8] ERR_LONGREAD_EN — ERR_LONGREAD_EN: enables err_longread
  [7] ERR_LINEWRITE_EN — ERR_LINEWRITE_EN: enables err_line_write
  [6] ERR_BURSTWRITE_EN — ERR_BURSTWRITE_EN: enables err_burst_write
  [5] ERR_SMALL_HEIGHT_EN — ERR_SMALL_HEIGHT_EN: enables detection of unaligned line number
  [4] ERR_SMALL_LENGTH_EN — ERR_SMALL_LENGTH_EN: enables detection of unaligned size
  [3] ERR_MISSING_VSYNC_EN — ERR_MISSING_VSYNC_EN: enables detection of missing VSYNC
  [2] ERR_MISSING_HSYNC_EN — ERR_MISSING_HSYNC_EN: enables detection of missing HSYNC
  [1] ERR_MISSING_DATA_EN — ERR_MISSING_DATA_EN: enables data miss detection
  [0] VSG_RUNNING_EN — VSG_RUNNING_EN: enables VSG status observation
0x144 DSI_TVG_STS_CTL — Control the enabling and edge detection of TVG status bits
  [16] TVG_STS_EDGE — TVG_STS_EDGE: edge detection of TVG status observation
  [0] TVG_STS_EN — TVG_STS_EN: enables TVG status observation
0x148 DSI_MCTL_DPHY_ERR_CTL1 — Controls the enabling and edge detection of the DPHY errors
  [n+21] ERR_CONT_LP1_{n}_EN (n=1..4), [n+17] ERR_CONT_LP0_{n}_EN (n=1..4), [n+13] ERR_CONTROL_{n}_EN (n=1..4), [n+9] ERR_SYNCESC_{n}_EN (n=1..4), [n+5] ERR_ESC_{n}_EN (n=1..4)
0x14C DSI_MCTL_DPHY_ERR_CTL2 — Controls he enabling and edge detection of the DPHY errors
  [n+15] ERR_CONT_LP1_{n}_EDGE (n=1..4), [n+11] ERR_CONT_LP0_{n}_EDGE (n=1..4), [n+7] ERR_CONTROL_{n}_EDGE (n=1..4), [n+3] ERR_SYNCESC_{n}_EDGE (n=1..4), [n-1] ERR_ESC_{n}_EDGE (n=1..4)
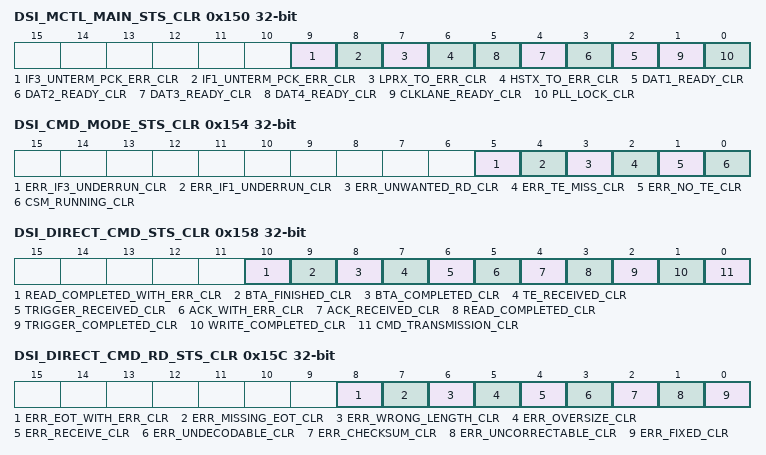
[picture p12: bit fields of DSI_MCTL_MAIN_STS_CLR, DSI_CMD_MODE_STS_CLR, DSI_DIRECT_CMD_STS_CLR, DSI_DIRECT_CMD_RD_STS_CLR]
0x150 DSI_MCTL_MAIN_STS_CLR wo — Main control status register clear function. These bits are spread across different register banks. The exact use of the set and reset is described in the section : Error and status bits. Write '1' to clear
  [9] IF3_UNTERM_PCK_ERR_CLR — IF3_UNTERM_PCK_ERR_CLR: clears if3_unterm_pck_err
  [8] IF1_UNTERM_PCK_ERR_CLR — IF1_UNTERM_PCK_ERR_CLR: clears if1_unterm_pck_err
  [7] LPRX_TO_ERR_CLR — LPRX_TO_ERR_CLR: clears lprx_to_err
  [6] HSTX_TO_ERR_CLR — HSTX_TO_ERR_CLR: clears hstx_to_err
  [n+1] DAT{n}_READY_CLR (n=1..4) — DAT{n}_READY_CLR: clears dat{n}_ready
  [1] CLKLANE_READY_CLR — CLKLANE_READY_CLR: clears clklane_ready
  [0] PLL_LOCK_CLR — PLL_LOCK_CLR: clears PLL lock
0x154 DSI_CMD_MODE_STS_CLR access per field — Command status register clear function. Write '1' to clear
  [5] ERR_IF3_UNDERRUN_CLR ro — ERR_IF3_UNDERRUN_CLR: clears err_IF3_underrun
  [4] ERR_IF1_UNDERRUN_CLR wo — ERR_IF1_UNDERRUN_CLR: clears err_IF1_underrun
  [3] ERR_UNWANTED_RD_CLR wo — ERR_UNWANTED_RD_CLR: clears err_unwanted_rd
  [2] ERR_TE_MISS_CLR wo — ERR_TE_MISS_CLR: clears err_te_miss
  [1] ERR_NO_TE_CLR wo — ERR_NO_TE_CLR: clears err_no_te
  [0] CSM_RUNNING_CLR wo — CSM_RUNNING_CLR: clears CSM running bit
0x158 DSI_DIRECT_CMD_STS_CLR wo — Direct command status register clear function. Write '1' to clear
  [10] READ_COMPLETED_WITH_ERR_CLR — READ_COMPLETED_WITH_ERR_CLR: clears detection of read completed with errors
  [9] BTA_FINISHED_CLR — BTA_FINISHED_CLR: clears BTA completion detection
  [8] BTA_COMPLETED_CLR — BTA_COMPLETED_CLR: clears BTA request completed
  [7] TE_RECEIVED_CLR — TE_RECEIVED_CLR: clears TE received
  [6] TRIGGER_RECEIVED_CLR — TRIGGER_RECEIVED_CLR: clears trigger
  [5] ACK_WITH_ERR_CLR — ACKNOWLEDGE_WITH_ERR_CLR: clears acknowledge with errors
  [4] ACK_RECEIVED_CLR — ACKNOWLEDGE_RECEIVED_CLR: clears acknowledge
  [3] READ_COMPLETED_CLR — READ_COMPLETED_CLR: clears read request completed
  [2] TRIGGER_COMPLETED_CLR — TRIGGER_COMPLETED_CLR: clears trigger request completed
  [1] WRITE_COMPLETED_CLR — WRITE_COMPLETED_CLR: clears detection of write request completed
  [0] CMD_TRANSMISSION_CLR — CMD_TRANSMISSION_CLR: clears cmd_transmission
0x15C DSI_DIRECT_CMD_RD_STS_CLR wo — Direct command read status register clear function. Write '1' to clear
  [8] ERR_EOT_WITH_ERR_CLR — ERR_EOT_WITH_ERR_CLR: clears err_eot_with_err
  [7] ERR_MISSING_EOT_CLR — ERR_MISSING_EOT_CLR: clears err_missing_eot
  [6] ERR_WRONG_LENGTH_CLR — ERR_WRONG_LENGTH_CLR: clears err_wrong_length
  [5] ERR_OVERSIZE_CLR — ERR_OVERSIZE_CLR: clears err_oversize
  [4] ERR_RECEIVE_CLR — ERR_RECEIVE_CLR: clears err_receive
  [3] ERR_UNDECODABLE_CLR — ERR_UNDECODABLE_CLR: clears err_undecodable
  [2] ERR_CHECKSUM_CLR — ERR_CHECKSUM_CLR: clears err_checksum
  [1] ERR_UNCORRECTABLE_CLR — ERR_UNCORRECTABLE_CLR: clears err_uncorrectable
  [0] ERR_FIXED_CLR — ERR_FIXED_CLR: clears err_fixed
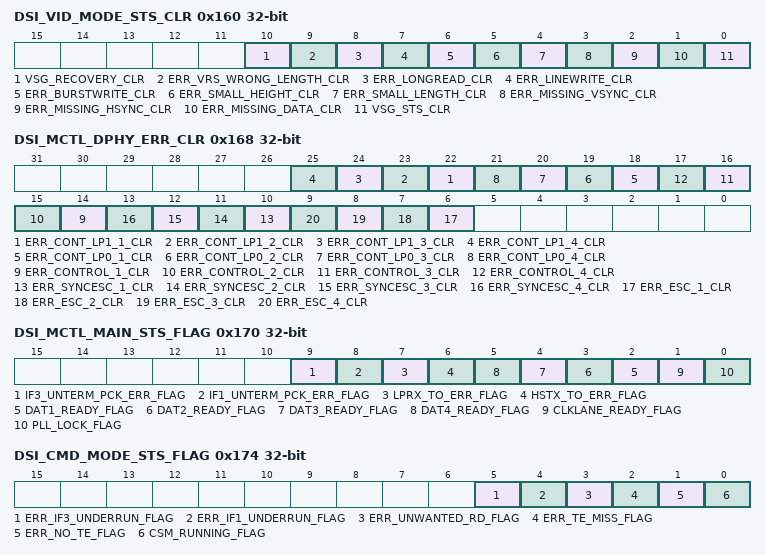
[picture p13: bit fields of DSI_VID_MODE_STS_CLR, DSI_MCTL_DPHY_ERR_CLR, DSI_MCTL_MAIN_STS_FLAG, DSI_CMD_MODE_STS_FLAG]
0x160 DSI_VID_MODE_STS_CLR wo — VSG status register clear function
  [10] VSG_RECOVERY_CLR — VSG_RECOVERY_CLR: clears the bit vsg_recovery
  [9] ERR_VRS_WRONG_LENGTH_CLR — ERR_VRS_WRONG_LENGTH_CLR: clears the bit err_vid_wrong_length
  [8] ERR_LONGREAD_CLR — ERR_LONGREAD_CLR: clears err_longread
  [7] ERR_LINEWRITE_CLR — ERR_LINEWRITE_CLR: clears err_linewrite
  [6] ERR_BURSTWRITE_CLR — ERR_BURSTWRITE_CLR: clears err_burstwrite
  [5] ERR_SMALL_HEIGHT_CLR — ERR_SMALL_HEIGHT_CLR: clears unaligned line number
  [4] ERR_SMALL_LENGTH_CLR — ERR_SMALL_LENGTH_CLR: clears analigned size
  [3] ERR_MISSING_VSYNC_CLR — ERR_MISSING_VSYNC_CLR: clears missing VSYNC
  [2] ERR_MISSING_HSYNC_CLR — ERR_MISSING_HSYNC_CLR: clears missing HSYNC
  [1] ERR_MISSING_DATA_CLR — ERR_MISSING_DATA_CLR: clears data miss
  [0] VSG_STS_CLR — VSG_STS_CLR: clears VSG status
0x164 DSI_TG_STS_CLR wo — TVG status register clear function. Write '1' to clear
  [0] TVG_STS_CLR — TVG_STS_CLR: clears TVG status observation
0x168 DSI_MCTL_DPHY_ERR_CLR wo — D_PHY lanes output register clear function. Write '1' to clear
  [n+21] ERR_CONT_LP1_{n}_CLR (n=1..4), [n+17] ERR_CONT_LP0_{n}_CLR (n=1..4), [n+13] ERR_CONTROL_{n}_CLR (n=1..4), [n+9] ERR_SYNCESC_{n}_CLR (n=1..4), [n+5] ERR_ESC_{n}_CLR (n=1..4)
0x170 DSI_MCTL_MAIN_STS_FLAG ro — Main control status Flag registers. The use of these registers is related to status and error bits management (and interrupt too). These bits are spread across different register banks. The exact use of the flag bit is described in the section : Error and status bits.
  [9] IF3_UNTERM_PCK_ERR_FLAG — IF3_UNTERM_PCK_ERR_FLAG: flags if3_unterm_pck_err
  [8] IF1_UNTERM_PCK_ERR_FLAG — IF1_UNTERM_PCK_ERR_FLAG: flags if1_unterm_pck_err
  [7] LPRX_TO_ERR_FLAG — LPRX_TO_ERR_FLAG: flags lprx_to_err
  [6] HSTX_TO_ERR_FLAG — HSTX_TO_ERR_FLAG: flags hstx_to_err
  [n+1] DAT{n}_READY_FLAG (n=1..4) — DAT{n}_READY_FLAG: flags dat{n}_ready
  [1] CLKLANE_READY_FLAG — CLKLANE_READY_FLAG: flags clklane_ready
  [0] PLL_LOCK_FLAG — PLL_LOCK_FLAG: flags PLL lock
0x174 DSI_CMD_MODE_STS_FLAG ro — Command Mode status
  [5] ERR_IF3_UNDERRUN_FLAG — ERR_IF3_UNDERRUN_FLAG: flags err_IF3_underrun
  [4] ERR_IF1_UNDERRUN_FLAG — ERR_IF1_UNDERRUN_FLAG: flags err_IF1_underrun
  [3] ERR_UNWANTED_RD_FLAG — ERR_UNWANTED_RD_FLAG: flags fixed_err
  [2] ERR_TE_MISS_FLAG — ERR_TE_MISS_FLAG: flags err_te_miss
  [1] ERR_NO_TE_FLAG — ERR_NO_TE_FLAG: flags err_no_te
  [0] CSM_RUNNING_FLAG — CSM_RUNNING_FLAG: flags remaining_err
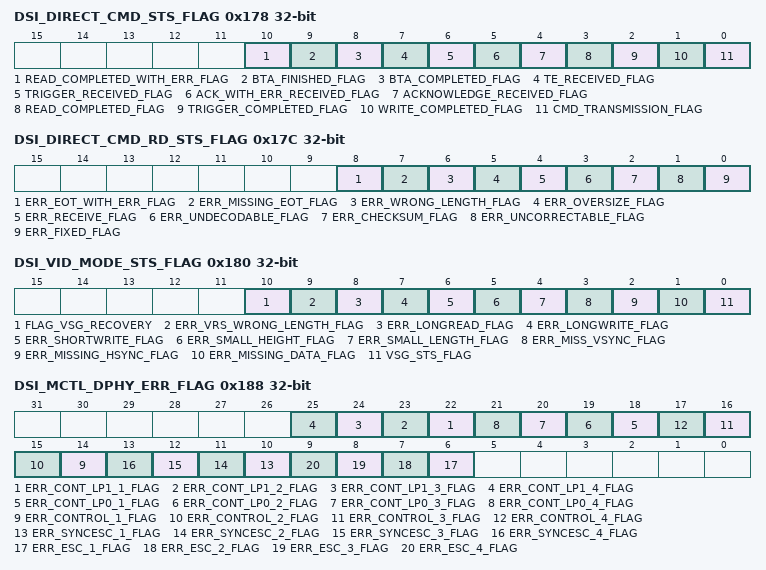
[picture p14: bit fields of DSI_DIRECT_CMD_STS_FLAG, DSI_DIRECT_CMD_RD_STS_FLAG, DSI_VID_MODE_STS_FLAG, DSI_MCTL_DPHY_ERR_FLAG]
0x178 DSI_DIRECT_CMD_STS_FLAG ro — Direct command mode status
  [10] READ_COMPLETED_WITH_ERR_FLAG — READ_COMPLETED_WITH_ERR_FLAG: flags detection of read completed with errors
  [9] BTA_FINISHED_FLAG — BTA_FINISHED_FLAG: flags BTA completion detection
  [8] BTA_COMPLETED_FLAG — BTA_COMPLETED_FLAG: flags BTA request completed
  [7] TE_RECEIVED_FLAG — TE_RECEIVED_FLAG: flags TE received
  [6] TRIGGER_RECEIVED_FLAG — TRIGGER_RECEIVED_FLAG: flags trigger
  [5] ACK_WITH_ERR_RECEIVED_FLAG — ACK_WITH_ERR_RECEIVED_FLAG: flag acknowledge with error detection
  [4] ACKNOWLEDGE_RECEIVED_FLAG — ACKNOWLEDGE_RECEIVED_FLAG: flags acknowledge
  [3] READ_COMPLETED_FLAG — READ_COMPLETED_FLAG: flags read request completed
  [2] TRIGGER_COMPLETED_FLAG — TRIGGER_COMPLETED_FLAG: flags trigger request completed
  [1] WRITE_COMPLETED_FLAG — WRITE_COMPLETED_FLAG: flags detection of write request completed
  [0] CMD_TRANSMISSION_FLAG — CMD_TRANSMISSION_FLAG: flags cmd_transmission
0x17C DSI_DIRECT_CMD_RD_STS_FLAG ro — Direct command read status bits
  [8] ERR_EOT_WITH_ERR_FLAG — ERR_EOT_WITH_ERR_FLAG: flags err_eot_with_err
  [7] ERR_MISSING_EOT_FLAG — ERR_MISSING_EOT_FLAG: flags err_missing_eot
  [6] ERR_WRONG_LENGTH_FLAG — ERR_WRONG_LENGTH_FLAG: flags err_wrong_length
  [5] ERR_OVERSIZE_FLAG — ERR_OVERSIZE_FLAG: flags err_oversize
  [4] ERR_RECEIVE_FLAG — ERR_RECEIVE_FLAG: flags err_receive
  [3] ERR_UNDECODABLE_FLAG — ERR_UNDECODABLE_FLAG: flags err_undecodable
  [2] ERR_CHECKSUM_FLAG — ERR_CHECKSUM_FLAG: flags err_checksum
  [1] ERR_UNCORRECTABLE_FLAG — ERR_UNCORRECTABLE_FLAG: flags err_uncorrectable
  [0] ERR_FIXED_FLAG — ERR_FIXED_FLAG: flags err_fixed
0x180 DSI_VID_MODE_STS_FLAG ro — Video Mode status flag
  [10] FLAG_VSG_RECOVERY — FLAG_VSG_RECOVERY: lags vsg_recovery
  [9] ERR_VRS_WRONG_LENGTH_FLAG — ERR_VRS_WRONG_LENGTH_FLAG: flags err_vrs_wrong_length
  [8] ERR_LONGREAD_FLAG — ERR_LONGREAD_FLAG: flags err_longread
  [7] ERR_LONGWRITE_FLAG — ERR_LONGWRITE_FLAG: flags err_longwrite
  [6] ERR_SHORTWRITE_FLAG — ERR_SHORTWRITE_FLAG: flags err_shortwrite
  [5] ERR_SMALL_HEIGHT_FLAG — ERR_SMALL_HEIGHT_FLAG: flags the detection of unaligned line number
  [4] ERR_SMALL_LENGTH_FLAG — ERR_SMALL_LENGTH_FLAG: flags the detection of unaligned size
  [3] ERR_MISS_VSYNC_FLAG — ERR_MISS_VSYNC_FLAG: flags missing VSYNC
  [2] ERR_MISSING_HSYNC_FLAG — ERR_MISSING_HSYNC_FLAG: flags missing HSYNC
  [1] ERR_MISSING_DATA_FLAG — ERR_MISSING_DATA_FLAG: flags data miss
  [0] VSG_STS_FLAG — VSG_STS_FLAG: flags VSG status
0x184 DSI_TG_STS_FLAG ro — TVG status Flags
  [0] TVG_STS_FLAG — TVG_STS_FLAG: Indicates TVG status observation
0x188 DSI_MCTL_DPHY_ERR_FLAG ro — Errors output from D_PHY lanes - flags error bit
  [n+21] ERR_CONT_LP1_{n}_FLAG (n=1..4), [n+17] ERR_CONT_LP0_{n}_FLAG (n=1..4), [n+13] ERR_CONTROL_{n}_FLAG (n=1..4), [n+9] ERR_SYNCESC_{n}_FLAG (n=1..4), [n+5] ERR_ESC_{n}_FLAG (n=1..4)
0x1A0 DSI_DPI_IRQ_EN — DPI interrupt enable
  [0] PIXEL_BUF_OVERFLOW_IRQ_EN — Enable DPI FIFO Overflow interrupt
0x1A4 DSI_DPI_IRQ_CLR wo — DPI interrupt clear register
  [0] PIXEL_BUF_OVERFLOW_IRQ_CLR — Clear DPI FIFO Overflow interrupt
0x1A8 DSI_DPI_IRQ_STS ro — DPI interrupt status
  [0] PIXEL_BUF_OVERFLOW_STS — Status of DPI FIFO Overflow interrupt
0x1AC DSI_DPI_CFG ro reset 0x8000000 — DPI interface configuration information
  [31:16] DPI_CFG_FIFODEPTH — DPI FIFO depth - configuration paramter
  [15:0] DPI_CFG_FIFO_LEVEL — DPI FIFO fill level - can be read mid-line for debug purposes, to allow adjustment of settings
0x1F0 DSI_TEST_GENERIC access per field — Generic test control and status register
  [31:16] STATUS ro — Test status - Value of test_generic_status input
  [15:0] CTRL rw — Test control - Drives test_generic_ctrl output
0x1FC DSI_ID_REG ro reset 0xCADD5131 — ID register for Controller
  [31:20] REV_VENDOR_ID — VENDOR_ID: IP vendor ID affected to IP [reset = 0xCAD].
  [19:12] REV_PRODUCT_ID — PRODUCT_ID: unique IP identifier within IP portfolio [reset = 0xD5].
  [11:8] REV_HARDWARE — H: Hardware revision number [reset = 0x1].
  [7:4] REV_X — X: Major revision value [reset = 0x3].
  [3:0] REV_Y — Y: Minor revision value [reset = 0x1].
0x200 DSI_ASF_INT_STATUS access not given — ASF Interrupt Status Register. This register indicates the source of ASF interrupts. The corresponding bit in the mask register must be clear for a bit to be set. If any bit is set in this register the asf_int_fatal or asf_int_nonfatal signal will be asserted. Writing to either raw or masked status registers, clear both registers. For test purposes, trigger signal interrupt event by writing to the ASF interrupt status test register.
  [6] ASF_INTEGRITY_ERR — Integrity error interrupt (access RW1C)
  [5] ASF_PROTOCOL_ERR — Protocol error interrupt (access RW1C)
  [4] ASF_TRANS_TO_ERR — Transaction timeouts error interrupt (access RW1C)
  [3] ASF_CSR_ERR — Configuration and status registers error interrupt (access RW1C)
  [2] ASF_DAP_ERR — Data and address paths parity error interrupt (access RW1C)
  [1] ASF_SRAM_UNCORR_ERR — SRAM uncorrectable error interrupt (access RW1C)
  [0] ASF_SRAM_CORR_ERR — SRAM correctable error interrupt (access RW1C)
0x204 DSI_ASF_INT_RAW_STATUS access not given — ASF Interrupt Raw Status Register. A bit set in this raw register indicates a source of ASF fault in the corresponding feature. Writing to either raw or masked status registers, clear both registers. For test purposes, trigger signal interrupt event by writing to the ASF interrupt status test register.
  fields as DSI_ASF_INT_STATUS
0x208 DSI_ASF_INT_MASK access per field reset 0x7F — The ASF interrupt mask register indicating which interrupt bits in the ASF interrupt status register are masked. All bits are set at reset. Clear the individual bit to enable the corresponding interrupt.
  [6] ASF_INTEGRITY_ERR_MASK rw — Mask bit for integrity error interrupt
  [5] ASF_PROTOCOL_ERR_MASK rw — Mask bit for protocol error interrupt.
  [4] ASF_TRANS_TO_ERR_MASK rw — Mask bit for transaction timeouts error interrupt.
  [3] ASF_CSR_ERR_MASK rw — Mask bit for configuration and status registers error interrupt.
  [2] ASF_DAP_ERR_MASK rw — Mask bit for data and address paths parity error interrupt.
  [1] ASF_SRAM_UNCORR_ERR_MASK rw — Mask bit for SRAM uncorrectable error interrupt.
  [0] ASF_SRAM_CORR_ERR_MASK rw — Mask bit for SRAM correctable error interrupt.
0x20C DSI_ASF_INT_TEST access per field — The ASF interrupt test register emulate hardware even. Write one to individual bit to trigger single event in (masked and raw) status registers according to mask and will generate interrupt accordingly.
  [6] ASF_INTEGRITY_ERR_TEST wo — Test bit for integrity error interrupt
  [5] ASF_PROTOCOL_ERR_TEST wo — Test bit for protocol error interrupt.
  [4] ASF_TRANS_TO_ERR_TEST wo — Test bit for transaction timeouts error interrupt.
  [3] ASF_CSR_ERR_TEST wo — Test bit for configuration and status registers error interrupt.
  [2] ASF_DAP_ERR_TEST wo — Test bit for data and address paths parity error interrupt.
  [1] ASF_SRAM_UNCORR_ERR_TEST wo — Test bit for SRAM uncorrectable error interrupt.
  [0] ASF_SRAM_CORR_ERR_TEST wo — Test bit for SRAM correctable error interrupt.
0x210 DSI_ASF_FATAL_NONFATAL_SELECT access per field reset 0x7F — The fatal or non-fatal interrupt register selects whether a fatal (asf_int_fatal) or non-fatal (asf_int_nonfatal) interrupt is triggered. If the bit of the event will be set to one then fatal interrupt (asf_int_fatal) will be triggered. Otherwise the non-fatal interrupt (asf_int_nonfatal) will be triggered.
  [6] ASF_INTEGRITY_ERR rw — Enable integrity error interrupt as fatal
  [5] ASF_PROTOCOL_ERR rw — Enable protocol error interrupt as fatal.
  [4] ASF_TRANS_TO_ERR rw — Enable transaction timeouts error interrupt as fatal.
  [3] ASF_CSR_ERR rw — Enable configuration and status registers error interrupt as fatal.
  [2] ASF_DAP_ERR rw — Enable data and address paths parity error interrupt as fatal.
  [1] ASF_SRAM_UNCORR_ERR rw — Enable SRAM uncorrectable error interrupt as fatal.
  [0] ASF_SRAM_CORR_ERR rw — Enable SRAM correctable error interrupt as fatal.
0x220 DSI_ASF_SRAM_CORR_FAULT_STATUS ro — Status register for SRAM correctable fault. These fields are updated whenever asf_sram_corr_fault input is active.
  [31:24] ASF_SRAM_CORR_FAULT_INST — Last SRAM instance that generated fault.
  [23:0] ASF_SRAM_CORR_FAULT_ADDR — Last SRAM address that generated fault.
0x224 DSI_ASF_SRAM_UNCORR_FAULT_STATUS ro — Status register for SRAM uncorrectable fault. These fields are updated whenever asf_sram_uncorr_fault input is active.
  [31:24] ASF_SRAM_UNCORR_FAULT_INST — Last SRAM instance that generated fault.
  [23:0] ASF_SRAM_UNCORR_FAULT_ADDR — Last SRAM address that generated fault.
0x228 DSI_ASF_SRAM_FAULT_STATS access not given — Statistics register for SRAM faults. Note that this register clears when software writes to any field.
  [15:0] ASF_SRAM_FAULT_CORR_STATS — Count of number of correctable errors if implemented. (access RW1C)
0x230 DSI_ASF_TRANS_TO_CTRL — Control register to configure the ASF transaction timeout monitors.
  [31] ASF_TRANS_TO_EN — Enable transaction timeout monitoring.
  [15:0] ASF_TRANS_TO_CTRL — Timer value to use for transaction timeout monitor.
0x234 DSI_ASF_TRANS_TO_FAULT_MASK reset 0xF — Control register to mask out ASF transaction timeout faults from triggering interrupts. On reset, all bits are set to mask out all sources. Clear the corresponding bit to enable the interrupt source. The width of this field is parameterisable and the bit definitions are implementation specific.
  [n] ASF_TRANS_TO_FAULT_{n}_MASK (n=0..3) — Mask register for each ASF transaction timeout fault source.
0x238 DSI_ASF_TRANS_TO_FAULT_STATUS access not given — Status register for transaction timeouts fault. If a fault occurs the revelant status bit will be set to 1. Each bit can be cleared by software writing 1 to each bit.
  [n] ASF_TRANS_TO_FAULT_{n}_STATUS (n=0..3) — Status bits for transaction timeouts faults. (access RW1C)
0x240 DSI_ASF_PROTOCOL_FAULT_MASK reset 0xF — Control register to mask out ASF Protocol faults from triggering interrupts. On reset, all bits are set to mask out all sources. Clear the corresponding bit to enable the interrupt source. The width of this field is parameterisable and the bit definitions are implementation specific.
  [n] ASF_PROTOCOL_FAULT_{n}_MASK (n=0..3) — Mask register for each ASF protocol fault source.
0x244 DSI_ASF_PROTOCOL_FAULT_STATUS access not given — Status register for protocol faults. If a fault occurs the revelant status bit will be set to 1. Each bit can be cleared by software writing 1 to each bit
  [n] ASF_PROTOCOL_FAULT_{n}_STATUS (n=0..3) — Status bits for protocol faults. (access RW1C)
